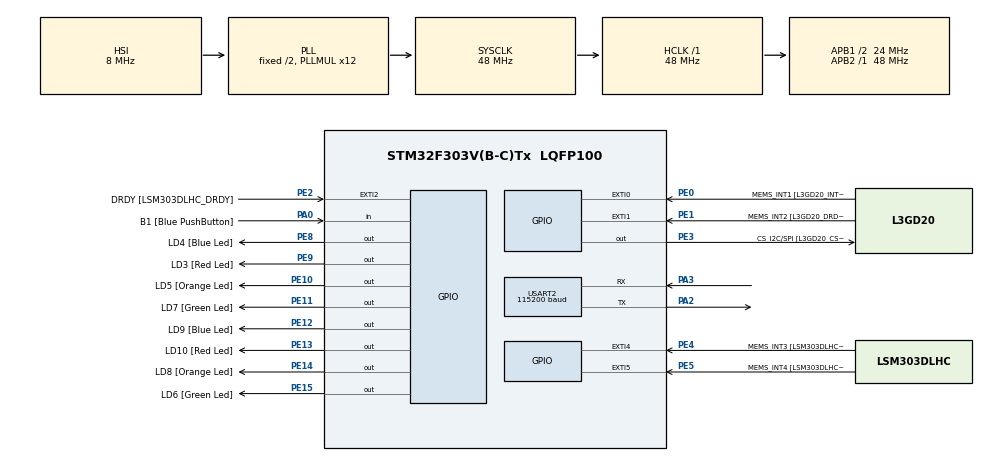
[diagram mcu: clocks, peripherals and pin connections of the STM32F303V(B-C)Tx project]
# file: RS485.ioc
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Mcu.Family=STM32F3
Mcu.Name=STM32F303V(B-C)Tx
Mcu.Package=LQFP100
NVIC.PriorityGroup=NVIC_PRIORITYGROUP_0
PA0.GPIO_Label=B1 [Blue PushButton]
PA0.GPIO_Mode=GPIO_MODE_INPUT
PA0.GPIO_PuPd=GPIO_NOPULL
PA0.Signal=GPIO_Input
PA11.GPIO_Label=DM
PA11.Signal=USB_DM
PA12.GPIO_Label=DP
PA12.Signal=USB_DP
PA13.GPIO_Label=SWDIO
PA13.Signal=SYS_JTMS-SWDIO
PA14.GPIO_Label=SWCLK
PA14.Signal=SYS_JTCK-SWCLK
PA2.Mode=Asynchronous
PA2.Signal=USART2_TX
PA3.Mode=Asynchronous
PA3.Signal=USART2_RX
PA5.GPIO_Label=SPI1_SCK [L3GD20_SCL/SPC]
PA5.GPIO_Mode=GPIO_MODE_AF_PP
PA5.GPIO_PuPd=GPIO_NOPULL
PA5.GPIO_Speed=GPIO_SPEED_FREQ_LOW
PA5.Signal=SPI1_SCK
PA6.GPIO_Label=SPI1_MISO [L3GD20_SA0/SDO]
PA6.GPIO_Mode=GPIO_MODE_AF_PP
PA6.GPIO_PuPd=GPIO_NOPULL
PA6.GPIO_Speed=GPIO_SPEED_FREQ_LOW
PA6.Signal=SPI1_MISO
PA7.GPIO_Label=SPI1_MISO [L3GD20_SDA/SDI/SDO]
PA7.GPIO_Mode=GPIO_MODE_AF_PP
PA7.GPIO_PuPd=GPIO_NOPULL
PA7.GPIO_Speed=GPIO_SPEED_FREQ_LOW
PA7.Signal=SPI1_MOSI
PB3.GPIO_Label=SWO
PB3.Signal=SYS_JTDO-TRACESWO
PB6.GPIO_FM6=__NULL
PB6.GPIO_Label=I2C1_SCL [LSM303DLHC_SCL]
PB6.GPIO_Mode=GPIO_MODE_AF_OD
PB6.GPIO_PuPd=GPIO_NOPULL
PB6.GPIO_Speed=GPIO_SPEED_FREQ_LOW
PB6.Signal=I2C1_SCL
PB7.GPIO_FM7=__NULL
PB7.GPIO_Label=I2C1_SDA [LSM303DLHC_SDA]
PB7.GPIO_Mode=GPIO_MODE_AF_OD
PB7.GPIO_PuPd=GPIO_NOPULL
PB7.GPIO_Speed=GPIO_SPEED_FREQ_LOW
PB7.Signal=I2C1_SDA
PC14-OSC32_IN.GPIO_Label=OSC32_IN
PC14-OSC32_IN.Signal=RCC_OSC32_IN
PC15-OSC32_OUT.GPIO_Label=OSC32_OUT
PC15-OSC32_OUT.Signal=RCC_OSC32_OUT
PE0.GPIO_Label=MEMS_INT1 [L3GD20_INT1]
PE0.GPIO_ModeDefaultEXTI=GPIO_MODE_EVT_RISING
PE0.GPIO_PuPd=GPIO_NOPULL
PE0.Signal=GPXTI0
PE1.GPIO_Label=MEMS_INT2 [L3GD20_DRDY/INT2]
PE1.GPIO_ModeDefaultEXTI=GPIO_MODE_EVT_RISING
PE1.GPIO_PuPd=GPIO_NOPULL
PE1.Signal=GPXTI1
PE10.GPIO_Label=LD5 [Orange Led]
PE10.GPIO_ModeDefaultOutputPP=GPIO_MODE_OUTPUT_PP
PE10.GPIO_PuPd=GPIO_NOPULL
PE10.GPIO_Speed=GPIO_SPEED_FREQ_LOW
PE10.Signal=GPIO_Output
PE11.GPIO_Label=LD7 [Green Led]
PE11.GPIO_ModeDefaultOutputPP=GPIO_MODE_OUTPUT_PP
PE11.GPIO_PuPd=GPIO_NOPULL
PE11.GPIO_Speed=GPIO_SPEED_FREQ_LOW
PE11.Signal=GPIO_Output
PE12.GPIO_Label=LD9 [Blue Led]
PE12.GPIO_ModeDefaultOutputPP=GPIO_MODE_OUTPUT_PP
PE12.GPIO_PuPd=GPIO_NOPULL
PE12.GPIO_Speed=GPIO_SPEED_FREQ_LOW
PE12.Signal=GPIO_Output
PE13.GPIO_Label=LD10 [Red Led]
PE13.GPIO_ModeDefaultOutputPP=GPIO_MODE_OUTPUT_PP
PE13.GPIO_PuPd=GPIO_NOPULL
PE13.GPIO_Speed=GPIO_SPEED_FREQ_LOW
PE13.Signal=GPIO_Output
PE14.GPIO_Label=LD8 [Orange Led]
PE14.GPIO_ModeDefaultOutputPP=GPIO_MODE_OUTPUT_PP
PE14.GPIO_PuPd=GPIO_NOPULL
PE14.GPIO_Speed=GPIO_SPEED_FREQ_LOW
PE14.Signal=GPIO_Output
PE15.GPIO_Label=LD6 [Green Led]
PE15.GPIO_ModeDefaultOutputPP=GPIO_MODE_OUTPUT_PP
PE15.GPIO_PuPd=GPIO_NOPULL
PE15.GPIO_Speed=GPIO_SPEED_FREQ_LOW
PE15.Signal=GPIO_Output
PE2.GPIO_Label=DRDY [LSM303DLHC_DRDY]
PE2.GPIO_ModeDefaultEXTI=GPIO_MODE_EVT_RISING
PE2.GPIO_PuPd=GPIO_NOPULL
PE2.Signal=GPXTI2
PE3.GPIO_Label=CS_I2C/SPI [L3GD20_CS_I2C/SPI]
PE3.GPIO_ModeDefaultOutputPP=GPIO_MODE_OUTPUT_PP
PE3.GPIO_PuPd=GPIO_NOPULL
PE3.GPIO_Speed=GPIO_SPEED_FREQ_LOW
PE3.Signal=GPIO_Output
PE4.GPIO_Label=MEMS_INT3 [LSM303DLHC_INT1]
PE4.GPIO_ModeDefaultEXTI=GPIO_MODE_EVT_RISING
PE4.GPIO_PuPd=GPIO_NOPULL
PE4.Signal=GPXTI4
PE5.GPIO_Label=MEMS_INT4 [LSM303DLHC_INT2]
PE5.GPIO_ModeDefaultEXTI=GPIO_MODE_EVT_RISING
PE5.GPIO_PuPd=GPIO_NOPULL
PE5.Signal=GPXTI5
PE8.GPIO_Label=LD4 [Blue Led]
PE8.GPIO_ModeDefaultOutputPP=GPIO_MODE_OUTPUT_PP
PE8.GPIO_PuPd=GPIO_NOPULL
PE8.GPIO_Speed=GPIO_SPEED_FREQ_LOW
PE8.Signal=GPIO_Output
PE9.GPIO_Label=LD3 [Red Led]
PE9.GPIO_ModeDefaultOutputPP=GPIO_MODE_OUTPUT_PP
PE9.GPIO_PuPd=GPIO_NOPULL
PE9.GPIO_Speed=GPIO_SPEED_FREQ_LOW
PE9.Signal=GPIO_Output
PF0-OSC_IN.GPIO_Label=OSC_IN
PF0-OSC_IN.Signal=RCC_OSC_IN
PF1-OSC_OUT.GPIO_Label=OSC_OUT
PF1-OSC_OUT.Signal=RCC_OSC_OUT
ProjectManager.HeapSize=0x200
ProjectManager.StackSize=0x400
ProjectManager.TargetToolchain=MDK-ARM V5
RCC.AHBFreq_Value=48000000
RCC.APB1CLKDivider=RCC_HCLK_DIV2
RCC.APB1Freq_Value=24000000
RCC.APB1TimFreq_Value=48000000
RCC.APB2Freq_Value=48000000
RCC.APB2TimFreq_Value=48000000
RCC.CortexFreq_Value=48000000
RCC.HCLKFreq_Value=48000000
RCC.HSE_VALUE=8000000
RCC.HSI_VALUE=8000000
RCC.LSE_VALUE=32768
RCC.PLLMUL=RCC_PLL_MUL12
RCC.SYSCLKFreq_VALUE=48000000
RCC.SYSCLKSourceVirtual=RCC_SYSCLKSOURCE_PLLCLK
RCC.USBFreq_Value=48000000
USART2.BaudRate=115200
USART2.Parity=PARITY_EVEN
USART2.TxPinLevelInvertParam=UART_ADVFEATURE_TXINV_DISABLE
board=STM32F3DISCOVERY

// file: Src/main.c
/**
  ******************************************************************************
  * File Name          : main.c
  * Description        : Main program body
  ******************************************************************************
  *
  * COPYRIGHT(c) 2017 STMicroelectronics
  *
  * Redistribution and use in source and binary forms, with or without modification,
  * are permitted provided that the following conditions are met:
  *   1. Redistributions of source code must retain the above copyright notice,
  *      this list of conditions and the following disclaimer.
  *   2. Redistributions in binary form must reproduce the above copyright notice,
  *      this list of conditions and the following disclaimer in the documentation
  *      and/or other materials provided with the distribution.
  *   3. Neither the name of STMicroelectronics nor the names of its contributors
  *      may be used to endorse or promote products derived from this software
  *      without specific prior written permission.
  *
  * THIS SOFTWARE IS PROVIDED BY THE COPYRIGHT HOLDERS AND CONTRIBUTORS "AS IS"
  * AND ANY EXPRESS OR IMPLIED WARRANTIES, INCLUDING, BUT NOT LIMITED TO, THE
  * IMPLIED WARRANTIES OF MERCHANTABILITY AND FITNESS FOR A PARTICULAR PURPOSE ARE
  * DISCLAIMED. IN NO EVENT SHALL THE COPYRIGHT HOLDER OR CONTRIBUTORS BE LIABLE
  * FOR ANY DIRECT, INDIRECT, INCIDENTAL, SPECIAL, EXEMPLARY, OR CONSEQUENTIAL
  * DAMAGES (INCLUDING, BUT NOT LIMITED TO, PROCUREMENT OF SUBSTITUTE GOODS OR
  * SERVICES; LOSS OF USE, DATA, OR PROFITS; OR BUSINESS INTERRUPTION) HOWEVER
  * CAUSED AND ON ANY THEORY OF LIABILITY, WHETHER IN CONTRACT, STRICT LIABILITY,
  * OR TORT (INCLUDING NEGLIGENCE OR OTHERWISE) ARISING IN ANY WAY OUT OF THE USE
  * OF THIS SOFTWARE, EVEN IF ADVISED OF THE POSSIBILITY OF SUCH DAMAGE.
  *
  ******************************************************************************
  */
#include "main.h"
#include "stm32f3xx_hal.h"

/* USER CODE BEGIN Includes */
#include <string.h>

/* USER CODE END Includes */

UART_HandleTypeDef huart2;

/* USER CODE BEGIN PV */
/* Private variables ---------------------------------------------------------*/

/* USER CODE END PV */

void SystemClock_Config(void);
void Error_Handler(void);
static void MX_GPIO_Init(void);
static void MX_USART2_UART_Init(void);

/* USER CODE BEGIN PFP */
/* Private function prototypes -----------------------------------------------*/

/* USER CODE END PFP */

int main(void)
{

  /* MCU Configuration----------------------------------------------------------*/

  /* Reset of all peripherals, Initializes the Flash interface and the Systick. */
  HAL_Init();

  /* Configure the system clock */
  SystemClock_Config();

  /* Initialize all configured peripherals */
  MX_GPIO_Init();
  MX_USART2_UART_Init();

  /* USER CODE BEGIN 2 */
		char *msg = "Hello World!!!\n\r";

		HAL_UART_Transmit(&huart2, (uint8_t*)msg, strlen(msg), 0xFFFF);
  /* USER CODE END 2 */

  /* Infinite loop */
  while (1)
  {

  }

}

/** System Clock Configuration
*/
void SystemClock_Config(void)
{

  RCC_OscInitTypeDef RCC_OscInitStruct;
  RCC_ClkInitTypeDef RCC_ClkInitStruct;
  RCC_PeriphCLKInitTypeDef PeriphClkInit;

    /**Initializes the CPU, AHB and APB busses clocks
    */
  RCC_OscInitStruct.OscillatorType = RCC_OSCILLATORTYPE_HSI;
  RCC_OscInitStruct.HSIState = RCC_HSI_ON;
  RCC_OscInitStruct.HSICalibrationValue = 16;
  RCC_OscInitStruct.PLL.PLLState = RCC_PLL_ON;
  RCC_OscInitStruct.PLL.PLLSource = RCC_PLLSOURCE_HSI;
  RCC_OscInitStruct.PLL.PLLMUL = RCC_PLL_MUL12;
  if (HAL_RCC_OscConfig(&RCC_OscInitStruct) != HAL_OK)
  {
    Error_Handler();
  }

    /**Initializes the CPU, AHB and APB busses clocks
    */
  RCC_ClkInitStruct.ClockType = RCC_CLOCKTYPE_HCLK|RCC_CLOCKTYPE_SYSCLK
                              |RCC_CLOCKTYPE_PCLK1|RCC_CLOCKTYPE_PCLK2;
  RCC_ClkInitStruct.SYSCLKSource = RCC_SYSCLKSOURCE_PLLCLK;
  RCC_ClkInitStruct.AHBCLKDivider = RCC_SYSCLK_DIV1;
  RCC_ClkInitStruct.APB1CLKDivider = RCC_HCLK_DIV2;
  RCC_ClkInitStruct.APB2CLKDivider = RCC_HCLK_DIV1;

  if (HAL_RCC_ClockConfig(&RCC_ClkInitStruct, FLASH_LATENCY_1) != HAL_OK)
  {
    Error_Handler();
  }

  PeriphClkInit.PeriphClockSelection = RCC_PERIPHCLK_USART2;
  PeriphClkInit.Usart2ClockSelection = RCC_USART2CLKSOURCE_PCLK1;
  if (HAL_RCCEx_PeriphCLKConfig(&PeriphClkInit) != HAL_OK)
  {
    Error_Handler();
  }

    /**Configure the Systick interrupt time
    */
  HAL_SYSTICK_Config(HAL_RCC_GetHCLKFreq()/1000);

    /**Configure the Systick
    */
  HAL_SYSTICK_CLKSourceConfig(SYSTICK_CLKSOURCE_HCLK);

  /* SysTick_IRQn interrupt configuration */
  HAL_NVIC_SetPriority(SysTick_IRQn, 0, 0);
}

/* USART2 init function */
static void MX_USART2_UART_Init(void)
{

  huart2.Instance = USART2;
  huart2.Init.BaudRate = 115200;
  huart2.Init.WordLength = UART_WORDLENGTH_8B;
  huart2.Init.StopBits = UART_STOPBITS_1;
  huart2.Init.Parity = UART_PARITY_EVEN;
  huart2.Init.Mode = UART_MODE_TX_RX;
  huart2.Init.HwFlowCtl = UART_HWCONTROL_NONE;
  huart2.Init.OverSampling = UART_OVERSAMPLING_16;
  huart2.Init.OneBitSampling = UART_ONE_BIT_SAMPLE_DISABLE;
  huart2.AdvancedInit.AdvFeatureInit = UART_ADVFEATURE_NO_INIT;
  if (HAL_UART_Init(&huart2) != HAL_OK)
  {
    Error_Handler();
  }

}

/** Configure pins as
        * Analog
        * Input
        * Output
        * EVENT_OUT
        * EXTI
     PA5   ------> SPI1_SCK
     PA6   ------> SPI1_MISO
     PA7   ------> SPI1_MOSI
     PA11   ------> USB_DM
     PA12   ------> USB_DP
     PB6   ------> I2C1_SCL
     PB7   ------> I2C1_SDA
*/
static void MX_GPIO_Init(void)
{

  GPIO_InitTypeDef GPIO_InitStruct;

  /* GPIO Ports Clock Enable */
  __HAL_RCC_GPIOE_CLK_ENABLE();
  __HAL_RCC_GPIOC_CLK_ENABLE();
  __HAL_RCC_GPIOF_CLK_ENABLE();
  __HAL_RCC_GPIOA_CLK_ENABLE();
  __HAL_RCC_GPIOB_CLK_ENABLE();

  /*Configure GPIO pin Output Level */
  HAL_GPIO_WritePin(GPIOE, CS_I2C_SPI_Pin|LD4_Pin|LD3_Pin|LD5_Pin
                          |LD7_Pin|LD9_Pin|LD10_Pin|LD8_Pin
                          |LD6_Pin, GPIO_PIN_RESET);

  /*Configure GPIO pins : DRDY_Pin MEMS_INT3_Pin MEMS_INT4_Pin MEMS_INT1_Pin
                           MEMS_INT2_Pin */
  GPIO_InitStruct.Pin = DRDY_Pin|MEMS_INT3_Pin|MEMS_INT4_Pin|MEMS_INT1_Pin
                          |MEMS_INT2_Pin;
  GPIO_InitStruct.Mode = GPIO_MODE_EVT_RISING;
  GPIO_InitStruct.Pull = GPIO_NOPULL;
  HAL_GPIO_Init(GPIOE, &GPIO_InitStruct);

  /*Configure GPIO pins : CS_I2C_SPI_Pin LD4_Pin LD3_Pin LD5_Pin
                           LD7_Pin LD9_Pin LD10_Pin LD8_Pin
                           LD6_Pin */
  GPIO_InitStruct.Pin = CS_I2C_SPI_Pin|LD4_Pin|LD3_Pin|LD5_Pin
                          |LD7_Pin|LD9_Pin|LD10_Pin|LD8_Pin
                          |LD6_Pin;
  GPIO_InitStruct.Mode = GPIO_MODE_OUTPUT_PP;
  GPIO_InitStruct.Pull = GPIO_NOPULL;
  GPIO_InitStruct.Speed = GPIO_SPEED_FREQ_LOW;
  HAL_GPIO_Init(GPIOE, &GPIO_InitStruct);

  /*Configure GPIO pin : B1_Pin */
  GPIO_InitStruct.Pin = B1_Pin;
  GPIO_InitStruct.Mode = GPIO_MODE_INPUT;
  GPIO_InitStruct.Pull = GPIO_NOPULL;
  HAL_GPIO_Init(B1_GPIO_Port, &GPIO_InitStruct);

  /*Configure GPIO pins : SPI1_SCK_Pin SPI1_MISO_Pin SPI1_MISOA7_Pin */
  GPIO_InitStruct.Pin = SPI1_SCK_Pin|SPI1_MISO_Pin|SPI1_MISOA7_Pin;
  GPIO_InitStruct.Mode = GPIO_MODE_AF_PP;
  GPIO_InitStruct.Pull = GPIO_NOPULL;
  GPIO_InitStruct.Speed = GPIO_SPEED_FREQ_LOW;
  GPIO_InitStruct.Alternate = GPIO_AF5_SPI1;
  HAL_GPIO_Init(GPIOA, &GPIO_InitStruct);

  /*Configure GPIO pins : DM_Pin DP_Pin */
  GPIO_InitStruct.Pin = DM_Pin|DP_Pin;
  GPIO_InitStruct.Mode = GPIO_MODE_AF_PP;
  GPIO_InitStruct.Pull = GPIO_NOPULL;
  GPIO_InitStruct.Speed = GPIO_SPEED_FREQ_HIGH;
  GPIO_InitStruct.Alternate = GPIO_AF14_USB;
  HAL_GPIO_Init(GPIOA, &GPIO_InitStruct);

  /*Configure GPIO pins : I2C1_SCL_Pin I2C1_SDA_Pin */
  GPIO_InitStruct.Pin = I2C1_SCL_Pin|I2C1_SDA_Pin;
  GPIO_InitStruct.Mode = GPIO_MODE_AF_OD;
  GPIO_InitStruct.Pull = GPIO_PULLUP;
  GPIO_InitStruct.Speed = GPIO_SPEED_FREQ_LOW;
  GPIO_InitStruct.Alternate = GPIO_AF4_I2C1;
  HAL_GPIO_Init(GPIOB, &GPIO_InitStruct);

}

void Error_Handler(void)
{
  while(1)
  {
  }
}

/************************ (C) COPYRIGHT STMicroelectronics *****END OF FILE****/
